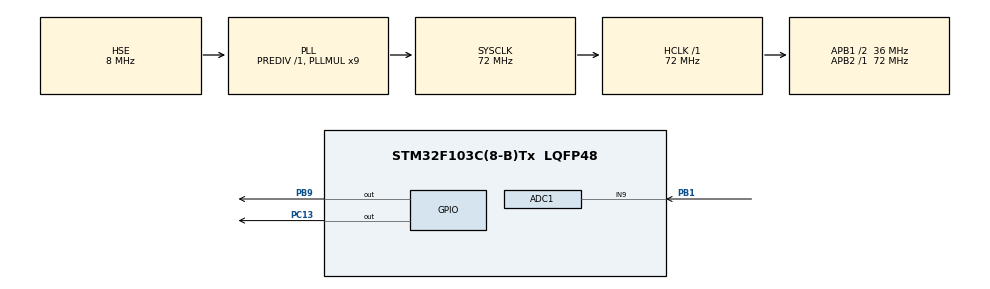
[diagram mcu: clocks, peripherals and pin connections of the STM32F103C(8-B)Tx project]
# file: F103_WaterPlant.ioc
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ADC1.Channel-0\#ChannelRegularConversion=ADC_CHANNEL_9
ADC1.NbrOfConversionFlag=1
ADC1.Rank-0\#ChannelRegularConversion=1
ADC1.SamplingTime-0\#ChannelRegularConversion=ADC_SAMPLETIME_1CYCLE_5
ADC1.master=1
Mcu.Family=STM32F1
Mcu.Name=STM32F103C(8-B)Tx
Mcu.Package=LQFP48
NVIC.PriorityGroup=NVIC_PRIORITYGROUP_4
PA13.Mode=Serial_Wire
PA13.Signal=SYS_JTMS-SWDIO
PA14.Mode=Serial_Wire
PA14.Signal=SYS_JTCK-SWCLK
PB1.Signal=ADCx_IN9
PB9.Signal=GPIO_Output
PC13-TAMPER-RTC.Signal=GPIO_Output
PC14-OSC32_IN.Mode=LSE-External-Oscillator
PC14-OSC32_IN.Signal=RCC_OSC32_IN
PC15-OSC32_OUT.Mode=LSE-External-Oscillator
PC15-OSC32_OUT.Signal=RCC_OSC32_OUT
PD0-OSC_IN.Mode=HSE-External-Oscillator
PD0-OSC_IN.Signal=RCC_OSC_IN
PD1-OSC_OUT.Mode=HSE-External-Oscillator
PD1-OSC_OUT.Signal=RCC_OSC_OUT
ProjectManager.HeapSize=0x200
ProjectManager.StackSize=0x400
ProjectManager.TargetToolchain=SW4STM32
RCC.ADCPresc=RCC_ADCPCLK2_DIV6
RCC.AHBFreq_Value=72000000
RCC.APB1CLKDivider=RCC_HCLK_DIV2
RCC.APB1Freq_Value=36000000
RCC.APB1TimFreq_Value=72000000
RCC.APB2Freq_Value=72000000
RCC.APB2TimFreq_Value=72000000
RCC.HCLKFreq_Value=72000000
RCC.HSIState=RCC_HSI_ON
RCC.PLLMUL=RCC_PLL_MUL9
RCC.PLLSourceVirtual=RCC_PLLSOURCE_HSE
RCC.SYSCLKFreq_VALUE=72000000
RCC.SYSCLKSource=RCC_SYSCLKSOURCE_PLLCLK
RCC.USBFreq_Value=72000000
SH.ADCx_IN9.0=ADC1_IN9,IN9
board=F103_WaterPlant

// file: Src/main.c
/**
  ******************************************************************************
  * File Name          : main.c
  * Description        : Main program body
  ******************************************************************************
  *
  * COPYRIGHT(c) 2017 STMicroelectronics
  *
  * Redistribution and use in source and binary forms, with or without modification,
  * are permitted provided that the following conditions are met:
  *   1. Redistributions of source code must retain the above copyright notice,
  *      this list of conditions and the following disclaimer.
  *   2. Redistributions in binary form must reproduce the above copyright notice,
  *      this list of conditions and the following disclaimer in the documentation
  *      and/or other materials provided with the distribution.
  *   3. Neither the name of STMicroelectronics nor the names of its contributors
  *      may be used to endorse or promote products derived from this software
  *      without specific prior written permission.
  *
  * THIS SOFTWARE IS PROVIDED BY THE COPYRIGHT HOLDERS AND CONTRIBUTORS "AS IS"
  * AND ANY EXPRESS OR IMPLIED WARRANTIES, INCLUDING, BUT NOT LIMITED TO, THE
  * IMPLIED WARRANTIES OF MERCHANTABILITY AND FITNESS FOR A PARTICULAR PURPOSE ARE
  * DISCLAIMED. IN NO EVENT SHALL THE COPYRIGHT HOLDER OR CONTRIBUTORS BE LIABLE
  * FOR ANY DIRECT, INDIRECT, INCIDENTAL, SPECIAL, EXEMPLARY, OR CONSEQUENTIAL
  * DAMAGES (INCLUDING, BUT NOT LIMITED TO, PROCUREMENT OF SUBSTITUTE GOODS OR
  * SERVICES; LOSS OF USE, DATA, OR PROFITS; OR BUSINESS INTERRUPTION) HOWEVER
  * CAUSED AND ON ANY THEORY OF LIABILITY, WHETHER IN CONTRACT, STRICT LIABILITY,
  * OR TORT (INCLUDING NEGLIGENCE OR OTHERWISE) ARISING IN ANY WAY OUT OF THE USE
  * OF THIS SOFTWARE, EVEN IF ADVISED OF THE POSSIBILITY OF SUCH DAMAGE.
  *
  ******************************************************************************
  */
#include "main.h"
#include "stm32f1xx_hal.h"
#include "adc.h"
#include "gpio.h"

/* USER CODE BEGIN Includes */
#define WATERING_PERIOD_HOURS 0
#define WATER_PUMP_ACTIVE_MS 2000

#define ADC_HUMIDITY_100_PRC 2662  // max is 0xFFF
#define HUMIDITY_LOW_THR_PRC 30
/* USER CODE END Includes */

/* USER CODE BEGIN PV */
/* Private variables ---------------------------------------------------------*/
extern ADC_HandleTypeDef hadc1;
int32_t last_watering_hrs = -WATERING_PERIOD_HOURS; // to be able to water immediately
/* USER CODE END PV */

void SystemClock_Config(void);
void Error_Handler(void);

/* USER CODE BEGIN PFP */
/* Private function prototypes -----------------------------------------------*/
#define DEBUG
#ifdef DEBUG
    #include <stdio.h>
    #include <stdlib.h>
	extern void initialise_monitor_handles(void);
    #define db_puts(s) puts(s)
    #define db_printf(szFormat, ...) printf(szFormat,##__VA_ARGS__)
#else
    #define db_puts(s)
    #define db_printf(szFormat, ...)
#endif
/* USER CODE END PFP */

/* USER CODE BEGIN 0 */

#define ms_to_hours(ms) (ms / 1000 / 3600)

uint32_t ADC1_GetValue(uint32_t channel) {

	ADC_ChannelConfTypeDef sConfig;

	sConfig.Channel = channel;
	sConfig.Rank = 1;
	sConfig.SamplingTime = ADC_SAMPLETIME_7CYCLES_5;
	HAL_ADC_ConfigChannel(&hadc1, &sConfig);

	// start conversion
	HAL_ADC_Start(&hadc1);

	// wait until finish
	HAL_ADC_PollForConversion(&hadc1, 100);

	uint32_t value = HAL_ADC_GetValue(&hadc1);

	HAL_ADC_Stop(&hadc1);

	return value;
}

uint8_t get_humidity() {
	uint32_t adc_val = ADC1_GetValue(ADC_CHANNEL_9);
	uint8_t humidity = (uint8_t) (adc_val * 100.0 / ADC_HUMIDITY_100_PRC);
	return humidity;
}

uint8_t need_to_water() {
	return get_humidity() < HUMIDITY_LOW_THR_PRC;
}

uint8_t can_water() {
	uint32_t curr_hrs = ms_to_hours(HAL_GetTick());
	return curr_hrs - last_watering_hrs >= WATERING_PERIOD_HOURS;
}

void print_debug_info() {
	uint8_t humidity = get_humidity();
	db_printf("ADC humidity %d %%, need to water %d, can water %d\n",
			humidity,
			need_to_water(),
			can_water());
}

void led_signal_need_to_water() {
	HAL_GPIO_WritePin(GPIOC, GPIO_PIN_13, 1 - need_to_water());  // inverse logic
}

void water_plant() {
	db_printf("\tWatering...\n");
	last_watering_hrs = ms_to_hours(HAL_GetTick());
	HAL_GPIO_WritePin(GPIOB, GPIO_PIN_9, GPIO_PIN_SET);
	HAL_Delay(WATER_PUMP_ACTIVE_MS);
	HAL_GPIO_WritePin(GPIOB, GPIO_PIN_9, GPIO_PIN_RESET);
}

/* USER CODE END 0 */

int main(void)
{

  /* USER CODE BEGIN 1 */
#ifdef DEBUG
    initialise_monitor_handles();
#endif

  /* USER CODE END 1 */

  /* MCU Configuration----------------------------------------------------------*/

  /* Reset of all peripherals, Initializes the Flash interface and the Systick. */
  HAL_Init();

  /* Configure the system clock */
  SystemClock_Config();

  /* Initialize all configured peripherals */
  MX_GPIO_Init();
  MX_ADC1_Init();

  /* Infinite loop */
  /* USER CODE BEGIN WHILE */
	while (1) {
#ifdef DEBUG
		print_debug_info();
#endif
		led_signal_need_to_water();
		if (need_to_water() && can_water()) {
			water_plant();
		}
		HAL_Delay(1000);
  /* USER CODE END WHILE */

	}

}

/** System Clock Configuration
*/
void SystemClock_Config(void)
{

  RCC_OscInitTypeDef RCC_OscInitStruct;
  RCC_ClkInitTypeDef RCC_ClkInitStruct;
  RCC_PeriphCLKInitTypeDef PeriphClkInit;

    /**Initializes the CPU, AHB and APB busses clocks
    */
  RCC_OscInitStruct.OscillatorType = RCC_OSCILLATORTYPE_HSE;
  RCC_OscInitStruct.HSEState = RCC_HSE_ON;
  RCC_OscInitStruct.HSEPredivValue = RCC_HSE_PREDIV_DIV1;
  RCC_OscInitStruct.HSIState = RCC_HSI_ON;
  RCC_OscInitStruct.PLL.PLLState = RCC_PLL_ON;
  RCC_OscInitStruct.PLL.PLLSource = RCC_PLLSOURCE_HSE;
  RCC_OscInitStruct.PLL.PLLMUL = RCC_PLL_MUL9;
  if (HAL_RCC_OscConfig(&RCC_OscInitStruct) != HAL_OK)
  {
    Error_Handler();
  }

    /**Initializes the CPU, AHB and APB busses clocks
    */
  RCC_ClkInitStruct.ClockType = RCC_CLOCKTYPE_HCLK|RCC_CLOCKTYPE_SYSCLK
                              |RCC_CLOCKTYPE_PCLK1|RCC_CLOCKTYPE_PCLK2;
  RCC_ClkInitStruct.SYSCLKSource = RCC_SYSCLKSOURCE_PLLCLK;
  RCC_ClkInitStruct.AHBCLKDivider = RCC_SYSCLK_DIV1;
  RCC_ClkInitStruct.APB1CLKDivider = RCC_HCLK_DIV2;
  RCC_ClkInitStruct.APB2CLKDivider = RCC_HCLK_DIV1;

  if (HAL_RCC_ClockConfig(&RCC_ClkInitStruct, FLASH_LATENCY_2) != HAL_OK)
  {
    Error_Handler();
  }

  PeriphClkInit.PeriphClockSelection = RCC_PERIPHCLK_ADC;
  PeriphClkInit.AdcClockSelection = RCC_ADCPCLK2_DIV6;
  if (HAL_RCCEx_PeriphCLKConfig(&PeriphClkInit) != HAL_OK)
  {
    Error_Handler();
  }

    /**Configure the Systick interrupt time
    */
  HAL_SYSTICK_Config(HAL_RCC_GetHCLKFreq()/1000);

    /**Configure the Systick
    */
  HAL_SYSTICK_CLKSourceConfig(SYSTICK_CLKSOURCE_HCLK);

  /* SysTick_IRQn interrupt configuration */
  HAL_NVIC_SetPriority(SysTick_IRQn, 0, 0);
}

void Error_Handler(void)
{
	while (1) {
	}
}

/************************ (C) COPYRIGHT STMicroelectronics *****END OF FILE****/
